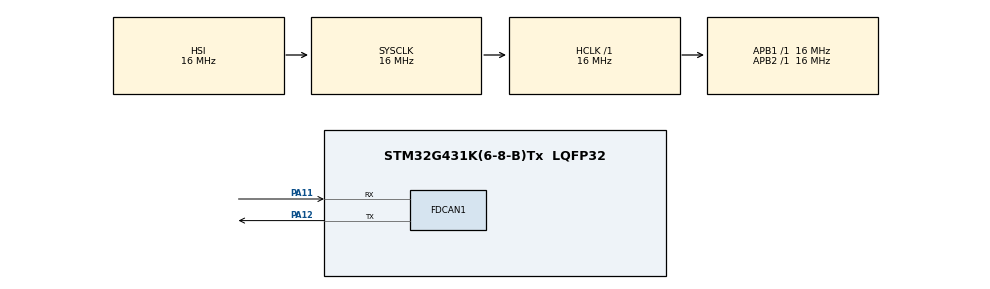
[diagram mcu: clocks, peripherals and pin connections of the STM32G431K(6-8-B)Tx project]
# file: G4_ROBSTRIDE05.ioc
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FDCAN1.CalculateBaudRateNominal=1000000
FDCAN1.CalculateTimeBitNominal=1000
FDCAN1.CalculateTimeQuantumNominal=62.5
FDCAN1.ExtFiltersNbr=1
FDCAN1.NominalPrescaler=1
FDCAN1.NominalTimeSeg1=11
FDCAN1.NominalTimeSeg2=4
Mcu.Family=STM32G4
Mcu.Name=STM32G431K(6-8-B)Tx
Mcu.Package=LQFP32
NVIC.FDCAN1_IT0_IRQn=true\:0\:0\:false\:false\:true\:true\:true\:true
NVIC.PriorityGroup=NVIC_PRIORITYGROUP_4
PA11.Mode=FDCAN_Activate
PA11.Signal=FDCAN1_RX
PA12.Mode=FDCAN_Activate
PA12.Signal=FDCAN1_TX
ProjectManager.HeapSize=0x200
ProjectManager.StackSize=0x400
ProjectManager.TargetToolchain=STM32CubeIDE
RCC.AHBFreq_Value=16000000
RCC.APB1Freq_Value=16000000
RCC.APB1TimFreq_Value=16000000
RCC.APB2Freq_Value=16000000
RCC.APB2TimFreq_Value=16000000
RCC.CortexFreq_Value=16000000
RCC.EXTERNAL_CLOCK_VALUE=12288000
RCC.HCLKFreq_Value=16000000
RCC.HSE_VALUE=8000000
RCC.HSI48_VALUE=48000000
RCC.HSI_VALUE=16000000
RCC.LSE_VALUE=32768
RCC.SYSCLKFreq_VALUE=16000000
RCC.USBFreq_Value=64000000
RCC.VCOOutputFreq_Value=128000000
VP_SYS_VS_DBSignals.Mode=DisableDeadBatterySignals
board=custom

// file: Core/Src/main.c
/* USER CODE BEGIN Header */
/**
  ******************************************************************************
  * @file           : main.c
  * @brief          : Main program body
  ******************************************************************************
  * @attention
  *
  * Copyright (c) 2025 STMicroelectronics.
  * All rights reserved.
  *
  * This software is licensed under terms that can be found in the LICENSE file
  * in the root directory of this software component.
  * If no LICENSE file comes with this software, it is provided AS-IS.
  *
  ******************************************************************************
  */
/* USER CODE END Header */
#include "main.h"

/* USER CODE BEGIN Includes */
#include "can.h"
//#include "gpio.h"
#include "Robstride.h"

/* USER CODE END Includes */

/* USER CODE BEGIN PD */
#define MASTER_ID    0xFD
#define MOTOR_ID     0x01
/* USER CODE END PD */

FDCAN_HandleTypeDef hfdcan1;

/* USER CODE BEGIN PV */
FDCAN_TxHeaderTypeDef TxHeader;
uint8_t TxData[8];
uint8_t RxData[8];
/* USER CODE END PV */

void SystemClock_Config(void);
static void MX_GPIO_Init(void);
static void MX_FDCAN1_Init(void);
/* USER CODE BEGIN PFP */
static void FDCAN1_Config(void){
	FDCAN_FilterTypeDef sFilterConfig;

	sFilterConfig.IdType = FDCAN_EXTENDED_ID;
	sFilterConfig.FilterIndex = 0;
	sFilterConfig.FilterType = FDCAN_FILTER_MASK;
	sFilterConfig.FilterConfig = FDCAN_FILTER_TO_RXFIFO0;
	sFilterConfig.FilterID1 = 0x000;
	sFilterConfig.FilterID2 = 0x000;
	if(HAL_FDCAN_ConfigFilter(&hfdcan1, &sFilterConfig) != HAL_OK){
		Error_Handler();
	}
	/* Configure global filter to reject all non-matching frames */
	if(HAL_FDCAN_ConfigGlobalFilter(&hfdcan1, FDCAN_REJECT, FDCAN_REJECT, FDCAN_REJECT_REMOTE, FDCAN_REJECT_REMOTE) != HAL_OK){
		Error_Handler();
	}
	if(HAL_FDCAN_Start(&hfdcan1) != HAL_OK){
		Error_Handler();
	}
	if(HAL_FDCAN_ActivateNotification(&hfdcan1, FDCAN_IT_RX_FIFO0_NEW_MESSAGE, 0) != HAL_OK){
		Error_Handler();
	}

	TxHeader.Identifier = 0x200;
	TxHeader.IdType = FDCAN_EXTENDED_ID;
	TxHeader.TxFrameType = FDCAN_DATA_FRAME;
	TxHeader.DataLength = 8;
	TxHeader.ErrorStateIndicator = FDCAN_ESI_ACTIVE;
	TxHeader.BitRateSwitch = FDCAN_BRS_OFF;
	TxHeader.FDFormat = FDCAN_CLASSIC_CAN;
	TxHeader.TxEventFifoControl = FDCAN_NO_TX_EVENTS;
	TxHeader.MessageMarker = 0;
}

void HAL_FDCAN_RxFifo0Callback(FDCAN_HandleTypeDef *hfdcan, uint32_t RxFifo0ITs){
	FDCAN_RxHeaderTypeDef RxHeader;

	if((RxFifo0ITs & FDCAN_IT_RX_FIFO0_NEW_MESSAGE) != RESET){
		if(HAL_FDCAN_GetRxMessage(hfdcan, FDCAN_RX_FIFO0, &RxHeader, RxData) != HAL_OK){
			Error_Handler();
		}
	}
}
/* USER CODE END PFP */

int main(void)
{

  /* MCU Configuration--------------------------------------------------------*/

  /* Reset of all peripherals, Initializes the Flash interface and the Systick. */
  HAL_Init();

  /* Configure the system clock */
  SystemClock_Config();

  /* Initialize all configured peripherals */
  MX_GPIO_Init();
  MX_FDCAN1_Init();
  /* USER CODE BEGIN 2 */
FDCAN1_Config();
	  //速度制御モード
	  TxHeader.Identifier = 0x1200FD01;
	  TxData[0] = 0x05;
	  TxData[1] = 0x70;
	  TxData[2] = 0x00;
	  TxData[3] = 0x00;
	  TxData[4] = 0x02;
	  TxData[5] = 0x00;
	  TxData[6] = 0x00;
	  TxData[7] = 0x00;
	  if(HAL_FDCAN_GetTxFifoFreeLevel(&hfdcan1)) {
	  	    	if(HAL_FDCAN_AddMessageToTxFifoQ(&hfdcan1, &TxHeader, TxData) != HAL_OK) {
	  	    		Error_Handler();
	  	    	}
	  	}

	  HAL_Delay(1000);
	  //モーター有効化
	  TxHeader.Identifier = 0x0300FD01;
	  TxData[0] = 0x00;
	  TxData[1] = 0x00;
	  TxData[2] = 0x00;
	  TxData[3] = 0x00;
	  TxData[4] = 0x00;
	  TxData[5] = 0x00;
	  TxData[6] = 0x00;
	  TxData[7] = 0x00;
	  if(HAL_FDCAN_GetTxFifoFreeLevel(&hfdcan1)) {
	  	    	if(HAL_FDCAN_AddMessageToTxFifoQ(&hfdcan1, &TxHeader, TxData) != HAL_OK) {
	  	    		Error_Handler();
	  	    	}
	  	}
  /* USER CODE END 2 */

  /* Infinite loop */
  /* USER CODE BEGIN WHILE */
  while (1)
  {
	  //通信タイプ0
	  TxHeader.Identifier = (0x00UL << 24) | (MASTER_ID << 8) | 2;;
	  TxData[0] = 0x00;
	  TxData[1] = 0x00;
	  TxData[2] = 0x00;
	  TxData[3] = 0x00;
	  TxData[4] = 0x00;
	  TxData[5] = 0x00;
	  TxData[6] = 0x00;
	  TxData[7] = 0x00;
	  if(HAL_FDCAN_GetTxFifoFreeLevel(&hfdcan1)) {
	  	    	if(HAL_FDCAN_AddMessageToTxFifoQ(&hfdcan1, &TxHeader, TxData) != HAL_OK) {
	  	    		Error_Handler();
	  	    	}
	  	}

	  HAL_Delay(1000);
    /* USER CODE END WHILE */

  }
}

void SystemClock_Config(void)
{
  RCC_OscInitTypeDef RCC_OscInitStruct = {0};
  RCC_ClkInitTypeDef RCC_ClkInitStruct = {0};

  /** Configure the main internal regulator output voltage
  */
  HAL_PWREx_ControlVoltageScaling(PWR_REGULATOR_VOLTAGE_SCALE1);

  /** Initializes the RCC Oscillators according to the specified parameters
  * in the RCC_OscInitTypeDef structure.
  */
  RCC_OscInitStruct.OscillatorType = RCC_OSCILLATORTYPE_HSI;
  RCC_OscInitStruct.HSIState = RCC_HSI_ON;
  RCC_OscInitStruct.HSICalibrationValue = RCC_HSICALIBRATION_DEFAULT;
  RCC_OscInitStruct.PLL.PLLState = RCC_PLL_NONE;
  if (HAL_RCC_OscConfig(&RCC_OscInitStruct) != HAL_OK)
  {
    Error_Handler();
  }

  /** Initializes the CPU, AHB and APB buses clocks
  */
  RCC_ClkInitStruct.ClockType = RCC_CLOCKTYPE_HCLK|RCC_CLOCKTYPE_SYSCLK
                              |RCC_CLOCKTYPE_PCLK1|RCC_CLOCKTYPE_PCLK2;
  RCC_ClkInitStruct.SYSCLKSource = RCC_SYSCLKSOURCE_HSI;
  RCC_ClkInitStruct.AHBCLKDivider = RCC_SYSCLK_DIV1;
  RCC_ClkInitStruct.APB1CLKDivider = RCC_HCLK_DIV1;
  RCC_ClkInitStruct.APB2CLKDivider = RCC_HCLK_DIV1;

  if (HAL_RCC_ClockConfig(&RCC_ClkInitStruct, FLASH_LATENCY_0) != HAL_OK)
  {
    Error_Handler();
  }
}

static void MX_FDCAN1_Init(void)
{

  hfdcan1.Instance = FDCAN1;
  hfdcan1.Init.ClockDivider = FDCAN_CLOCK_DIV1;
  hfdcan1.Init.FrameFormat = FDCAN_FRAME_CLASSIC;
  hfdcan1.Init.Mode = FDCAN_MODE_NORMAL;
  hfdcan1.Init.AutoRetransmission = DISABLE;
  hfdcan1.Init.TransmitPause = DISABLE;
  hfdcan1.Init.ProtocolException = DISABLE;
  hfdcan1.Init.NominalPrescaler = 1;
  hfdcan1.Init.NominalSyncJumpWidth = 1;
  hfdcan1.Init.NominalTimeSeg1 = 11;
  hfdcan1.Init.NominalTimeSeg2 = 4;
  hfdcan1.Init.DataPrescaler = 1;
  hfdcan1.Init.DataSyncJumpWidth = 1;
  hfdcan1.Init.DataTimeSeg1 = 1;
  hfdcan1.Init.DataTimeSeg2 = 1;
  hfdcan1.Init.StdFiltersNbr = 0;
  hfdcan1.Init.ExtFiltersNbr = 1;
  hfdcan1.Init.TxFifoQueueMode = FDCAN_TX_FIFO_OPERATION;
  if (HAL_FDCAN_Init(&hfdcan1) != HAL_OK)
  {
    Error_Handler();
  }

}

static void MX_GPIO_Init(void)
{

  /* GPIO Ports Clock Enable */
  __HAL_RCC_GPIOA_CLK_ENABLE();

}

void Error_Handler(void)
{
  __disable_irq();
  while (1)
  {
  }
}
